# DA14682 register map
Vendor: Dialog; Series: DA14682; File version: 1.2
CPU: CM0 r1p0, little endian, MPU, FPU, 3 interrupt priority bits
Registers are 16-bit, read-write, reset 0x0 unless marked. A register's access mark holds for its fields unless they carry their own. Offsets are from the block's base; [hi:lo] are bit positions; {n}, {i} and the like mark numbered series; 'fields as' and 'values as' point back to an identical list.

## DMA — DMA registers
Base 0x50003500
{0x0+0x10*i} DMA{i}_A_STARTL_REG (i=0..6) — Start address Low A of DMA channel {i}
  [15:0] DMA{i}_A_STARTL — Source start address, lower 16 bits
{0x2+0x10*i} DMA{i}_A_STARTH_REG (i=0..6) — Start address High A of DMA channel {i}
  [15:0] DMA{i}_A_STARTH — Source start address, upper 16 bits
{0x4+0x10*i} DMA{i}_B_STARTL_REG (i=0..6) — Start address Low B of DMA channel {i}
  [15:0] DMA{i}_B_STARTL — Destination start address, lower 16 bits
{0x6+0x10*i} DMA{i}_B_STARTH_REG (i=0..6) — Start address High B of DMA channel {i}
  [15:0] DMA{i}_B_STARTH — Destination start address, upper 16 bits
{0x8+0x10*i} DMA{i}_INT_REG (i=0..7) — DMA receive interrupt register channel {i}
  [15:0] DMA{i}_INT — Number of transfers until an interrupt is generated. The interrupt is generated after a transfer, if DMAx_INT_REG is equal to DMAx_IDX_REG and before DMAx_IDX_REG is incremented. The bit-field IRQ_ENABLE of DMAx_CTRL_REG must be set to '1' to let the controller generate the interrupt.
{0xA+0x10*i} DMA{i}_LEN_REG (i=0..7) — DMA receive length register channel {i}
  [15:0] DMA{i}_LEN — DMA channel's transfer length. DMAx_LEN of value 0, 1, 2, ... results into an actual transfer length of 1, 2, 3, ...
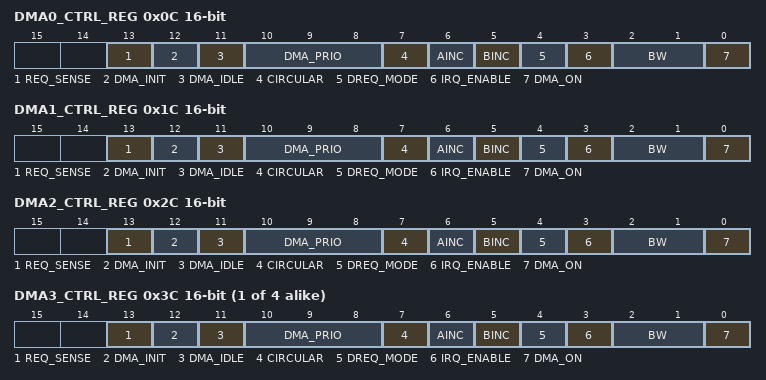
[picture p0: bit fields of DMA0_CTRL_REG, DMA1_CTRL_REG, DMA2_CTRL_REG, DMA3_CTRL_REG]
0x0C DMA0_CTRL_REG — Control register for the DMA channel 0
  [13] REQ_SENSE — 0 = DMA operates with level-sensitive peripheral requests (default) 1 = DMA operates with (positive) edge-sensitive peripheral requests
  [12] DMA_INIT — 0 = DMA performs copy A1 to B1, A2 to B2, etc ... 1 = DMA performs copy of A1 to B1, B2, etc ... This feature is useful for memory initialization to any value. Thus, BINC must be set to '1', while AINC is don't care, as only one fetch from A is done. This process cannot be interrupted by other DMA channels. It is also noted that DMA_INIT should not be used when DREQ_MODE='1'.
  [11] DMA_IDLE — 0 = Blocking mode, the DMA performs a fast back-to-back copy, disabling bus access for any bus master with lower priority. 1 = Interrupting mode, the DMA inserts a wait cycle after each store allowing the CPU to steal cycles or cache to perform a burst read. If DREQ_MODE='1', DMA_IDLE is don't care.
  [10:8] DMA_PRIO — The priority level determines which DMA channel will be granted access for transferring data, in case more than one channels are active and request the bus at the same time. The greater the value, the higher the priority. In specific: 000 = lowest priority 111 = highest priority If different channels with equal priority level values request the bus at the same time, an inherent priority mechanism is applied. According to this mechanism, if, for example, both the DMA0 and DMA1 channels have the same priority level, then DMA0 will first be granted access to the bus.
  [7] CIRCULAR — 0 = Normal mode. The DMA channel stops after having completed the transfer of length determined by DMAx_LEN_REG. DMA_ON automatically deasserts when the transfer is completed. 1 = Circular mode (applicable only if DREQ_MODE = '1'). In this mode, DMA_ON never deasserts, as the DMA channel automatically resets DMAx_IDX_REG and starts a new transfer.
  [6] AINC — Enable increment of source address. 0 = do not increment (source address stays the same during the transfer) 1 = increment according to the value of BW bit-field (by 1, when BW="00" ; by 2, when BW="01" ; by 4, when BW="10")
  [5] BINC — Enable increment of destination address. 0 = do not increment (destination address stays the same during the transfer) 1 = increment according to the value of BW bit-field (by 1, when BW="00" ; by 2, when BW="01" ; by 4, when BW="10")
  [4] DREQ_MODE — 0 = DMA channel starts immediately 1 = DMA channel must be triggered by peripheral DMA request (see also the description of DMA_REQ_MUX_REG)
  [3] IRQ_ENABLE — 0 = disable interrupt on this channel 1 = enable interrupt on this channel
  [2:1] BW — Bus transfer width: 00 = 1 Byte (suggested for peripherals like UART and 8-bit SPI) 01 = 2 Bytes (suggested for peripherals like I2C and 16-bit SPI) 10 = 4 Bytes (suggested for Memory-to-Memory transfers) 11 = Reserved
  [0] DMA_ON — 0 = DMA channel is off, clocks are disabled 1 = DMA channel is enabled. This bit will be automatically cleared after the completion of a transfer, if circular mode is not enabled. In circular mode, this bit stays set.
{0xE+0x10*i} DMA{i}_IDX_REG (i=0..7) — Index value of DMA channel {i}
  [15:0] DMA{i}_IDX ro — This (read-only) register determines the data items currently fetched by the DMA channel, during an on-going transfer. When the transfer is completed, the register is automatically reset to 0. The DMA channel uses this register to form the source/destination address of the next DMA cycle, considering also AINC/BINC and BW.
0x1C DMA1_CTRL_REG — Control register for the DMA channel 1
  fields as DMA0_CTRL_REG
0x2C DMA2_CTRL_REG — Control register for the DMA channel 2
  [13] REQ_SENSE — 0 = DMA operates with level-sensitive peripheral requests (default) 1 = DMA operates with (positive) edge-sensitive peripheral requests
  [12] DMA_INIT — 0 = DMA performs copy A1 to B1, A2 to B2, etc ... 1 = DMA performs copy of A1 to B1, B2, etc ... This feature is useful for memory initialization to any value. Thus, BINC must be set to '1', while AINC is don't care, as only one fetch from A is done. This process cannot be interrupted by other DMA channels. It is also noted that DMA_INIT should not be used when DREQ_MODE='1'.
  [11] DMA_IDLE — 0 = Blocking mode, the DMA performs a fast back-to-back copy, disabling bus access for any bus master with lower priority. 1 = Interrupting mode, the DMA inserts a wait cycle after each store allowing the CPU to steal cycles or cache to perform a burst read. If DREQ_MODE='1', DMA_IDLE is don't care.
  [10:8] DMA_PRIO — The priority level determines which DMA channel will be granted access for transferring data, in case more than one channels are active and request the bus at the same time. The greater the value, the higher the priority. In specific: 000 = lowest priority 111 = highest priority If different channels with equal priority level values request the bus at the same time, an inherent priority mechanism is applied. According to this mechanism, if, for example, both the DMA0 and DMA1 channels have the same priority level, then DMA0 will first be granted access to the bus.
  [7] CIRCULAR — 0 = Normal mode. The DMA channel stops after having completed the transfer of length determined by DMAx_LEN_REG. DMA_ON automatically deasserts when the transfer is completed. 1 = Circular mode (applicable only if DREQ_MODE = '1'). In this mode, DMA_ON never deasserts, as the DMA channel automatically resets DMAx_IDX_REG and starts a new transfer.
  [6] AINC — Enable increment of destination address. 0 = do not increment (destination address stays the same during the transfer) 1 = increment according to the value of BW bit-field (by 1, when BW="00" ; by 2, when BW="01" ; by 4, when BW="10")
  [5] BINC — Enable increment of destination address 0 = do not increment 1 = increment according value of BW
  [4] DREQ_MODE — 0 = DMA channel starts immediately 1 = DMA channel must be triggered by peripheral DMA request (see also the description of DMA_REQ_MUX_REG)
  [3] IRQ_ENABLE — 0 = disable interrupt on this channel 1 = enable interrupt on this channel
  [2:1] BW — Bus transfer width: 00 = 1 Byte (suggested for peripherals like UART and 8-bit SPI) 01 = 2 Bytes (suggested for peripherals like I2C and 16-bit SPI) 10 = 4 Bytes (suggested for Memory-to-Memory transfers) 11 = Reserved
  [0] DMA_ON — 0 = DMA channel is off, clocks are disabled 1 = DMA channel is enabled. This bit will be automatically cleared after the completion of a transfer, if circular mode is not enabled. In circular mode, this bit stays set.
{0xC+0x10*i} DMA{i}_CTRL_REG (i=3..6) — Control register for the DMA channel {i}
  fields as DMA0_CTRL_REG
0x70 DMA7_A_STARTL_REG — Start address Low A of DMA channel 7
  [15:0] DMA7_A_STARTL — Source start address, lower 16 bits NOTE: See also the DMA chapter of the Datasheet for the allowed range of the DMA7 source address in Secure Boot mode.
0x72 DMA7_A_STARTH_REG — Start address High A of DMA channel 7
  [15:0] DMA7_A_STARTH — Source start address, upper 16 bits NOTE: See also the DMA chapter of the Datasheet for the allowed range of the DMA7 source address in Secure Boot mode.
0x74 DMA7_B_STARTL_REG — Start address Low B of DMA channel 7
  [15:0] DMA7_B_STARTL — Destination start address, lower 16 bits NOTE: In Secure Boot mode, this register is overruled to the lower 16 bits of address CRYPTO_KEYS_START_ADDR.
0x76 DMA7_B_STARTH_REG — Start address High B of DMA channel 7
  [15:0] DMA7_B_STARTH — Destination start address, upper 16 bits NOTE: In Secure Boot mode, this register is overruled to the higher 16 bits of address CRYPTO_KEYS_START_ADDR.
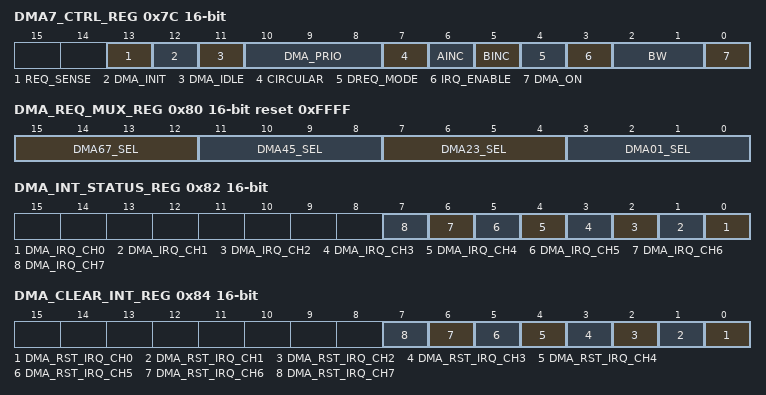
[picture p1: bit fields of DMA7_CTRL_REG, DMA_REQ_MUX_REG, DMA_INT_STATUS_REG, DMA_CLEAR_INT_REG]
0x7C DMA7_CTRL_REG — Control register for the DMA channel 7
  [13] REQ_SENSE — 0 = DMA operates with level-sensitive peripheral requests (default) 1 = DMA operates with (positive) edge-sensitive peripheral requests
  [12] DMA_INIT — 0 = DMA performs copy A1 to B1, A2 to B2, etc ... 1 = DMA performs copy of A1 to B1, B2, etc ... This feature is useful for memory initialization to any value. Thus, BINC must be set to '1', while AINC is don't care, as only one fetch from A is done. This process cannot be interrupted by other DMA channels. It is also noted that DMA_INIT should not be used when DREQ_MODE='1'. NOTE: This bit-field is overruled to '0' when the DMA7 channel is configured as "trusted" channel (in Secure Boot mode).
  [11] DMA_IDLE — 0 = Blocking mode, the DMA performs a fast back-to-back copy, disabling bus access for any bus master with lower priority. 1 = Interrupting mode, the DMA inserts a wait cycle after each store allowing the CPU to steal cycles or cache to perform a burst read. If DREQ_MODE='1', DMA_IDLE is don't care. *NOTE: This bit-field is overruled to '0' when the DMA7 channel is configured as "trusted" channel (in Secure Boot mode).
  [10:8] DMA_PRIO — The priority level determines which DMA channel will be granted access for transferring data, in case more than one channels are active and request the bus at the same time. The greater the value, the higher the priority. In specific: 000 = lowest priority 111 = highest priority If different channels with equal priority level values request the bus at the same time, an inherent priority mechanism is applied. According to this mechanism, if, for example, both the DMA0 and DMA1 channels have the same priority level, then DMA0 will first be granted access to the bus.
  [7] CIRCULAR — 0 = Normal mode. The DMA channel stops after having completed the transfer of length determined by DMAx_LEN_REG. DMA_ON automatically deasserts when the transfer is completed. 1 = Circular mode (applicable only if DREQ_MODE = '1'). In this mode, DMA_ON never deasserts, as the DMA channel automatically resets DMAx_IDX_REG and starts a new transfer.
  [6] AINC — Enable increment of source address. 0 = do not increment (source address stays the same during the transfer) 1 = increment according to the value of BW bit-field (by 1, when BW="00" ; by 2, when BW="01" ; by 4, when BW="10")
  [5] BINC — Enable increment of destination address. 0 = do not increment (destination address stays the same during the transfer) 1 = increment according to the value of BW bit-field (by 1, when BW="00" ; by 2, when BW="01" ; by 4, when BW="10")
  [4] DREQ_MODE — 0 = DMA channel starts immediately 1 = DMA channel must be triggered by peripheral DMA request (see also the description of DMA_REQ_MUX_REG) *NOTE: This bit-field is overruled to '0' when channel DMA7 is configured as "trusted" channel (in Secure Boot mode).
  [3] IRQ_ENABLE — 0 = disable interrupt on this channel 1 = enable interrupt on this channel
  [2:1] BW — Bus transfer width: 00 = 1 Byte (suggested for peripherals like UART and 8-bit SPI) 01 = 2 Bytes (suggested for peripherals like I2C and 16-bit SPI) 10 = 4 Bytes (suggested for Memory-to-Memory transfers) 11 = Reserved NOTE: This bit-field is overruled to "10" when channel DMA7 is configured as "trusted" channel (in Secure Boot mode).
  [0] DMA_ON — 0 = DMA channel is off, clocks are disabled 1 = DMA channel is enabled. This bit will be automatically cleared after the completion of a transfer, if circular mode is not enabled. In circular mode, this bit stays set.
0x80 DMA_REQ_MUX_REG reset 0xFFFF — DMA channel assignments
  [15:12] DMA67_SEL — Select which combination of peripherals are mapped on the DMA channels. The peripherals are mapped as pairs on two channels. Here, the first DMA request is mapped on channel 6 and the second on channel 7. See DMA01_SEL for the peripheral mapping.
  [11:8] DMA45_SEL — Select which combination of peripherals are mapped on the DMA channels. The peripherals are mapped as pairs on two channels. Here, the first DMA request is mapped on channel 4 and the second on channel 5. See DMA01_SEL for the peripherals' mapping.
  [7:4] DMA23_SEL — Select which combination of peripherals are mapped on the DMA channels. The peripherals are mapped as pairs on two channels. Here, the first DMA request is mapped on channel 2 and the second on channel 3. See DMA01_SEL for the peripherals' mapping.
  [3:0] DMA01_SEL — Select which combination of peripherals are mapped on the DMA channels. The peripherals are mapped as pairs on two channels. Here, the first DMA request is mapped on channel 0 and the second on channel 1. 0x0: SPI_rx / SPI_tx 0x1: SPI2_rx / SPI2_tx 0x2: UART_rx / UART_tx 0x3: UART2_rx / UART2_tx 0x4: I2C_rx / I2C_tx 0x5: I2C2_rx / I2C2_tx 0x6: USB_rx / USB_tx 0x7: Reserved 0x8: PCM_rx / PCM_tx 0x9: SRC_rx / SRC_tx (for all the supported conversions) 0xA: FTDF_rx / FTDF_tx 0xB: Reserved 0xC: ADC / - 0xD: Reserved 0xE: Reserved 0xF: None Note: If any of the four available peripheral selector fields (DMA01_SEL, DMA23_SEL, DMA45_SEL, DMA67_SEL) have the same value, the lesser significant selector has higher priority and will control the dma acknowledge. Hence, if DMA01_SEL = DMA23_SEL, the channels 0 and 1 will generate the DMA acknowledge signals for the selected peripheral. Consequently, it is suggested to assign the intended peripheral value to a unique selector field.
0x82 DMA_INT_STATUS_REG — DMA interrupt status register
  [n] DMA_IRQ_CH{n} ro (n=0..7) — 0: IRQ on channel {n} is not set 1: IRQ on channel {n} is set
0x84 DMA_CLEAR_INT_REG — DMA clear interrupt register
  [n] DMA_RST_IRQ_CH{n} wo (n=0..7) — Writing a 1 will reset the status bit of DMA_INT_STATUS_REG for channel {n} ; writing a 0 will have no effect
